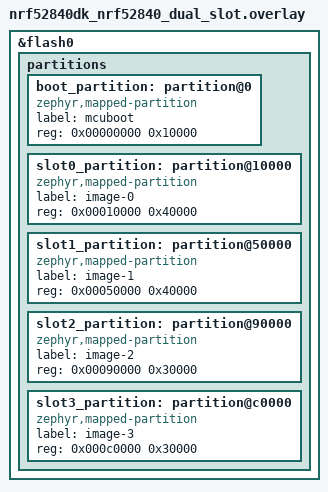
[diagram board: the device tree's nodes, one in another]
/*
 * Copyright 2024 Nordic Semiconductor ASA
 *
 * SPDX-License-Identifier: Apache-2.0
 */

/delete-node/ &boot_partition;
/delete-node/ &slot0_partition;
/delete-node/ &slot1_partition;

&flash0 {
	partitions {
		boot_partition: partition@0 {
			compatible = "zephyr,mapped-partition";
			label = "mcuboot";
			reg = <0x00000000 0x10000>;
		};

		slot0_partition: partition@10000 {
			compatible = "zephyr,mapped-partition";
			label = "image-0";
			reg = <0x00010000 0x40000>;
		};

		slot1_partition: partition@50000 {
			compatible = "zephyr,mapped-partition";
			label = "image-1";
			reg = <0x00050000 0x40000>;
		};

		slot2_partition: partition@90000 {
			compatible = "zephyr,mapped-partition";
			label = "image-2";
			reg = <0x00090000 0x30000>;
		};

		slot3_partition: partition@c0000 {
			compatible = "zephyr,mapped-partition";
			label = "image-3";
			reg = <0x000c0000 0x30000>;
		};
	};
};
